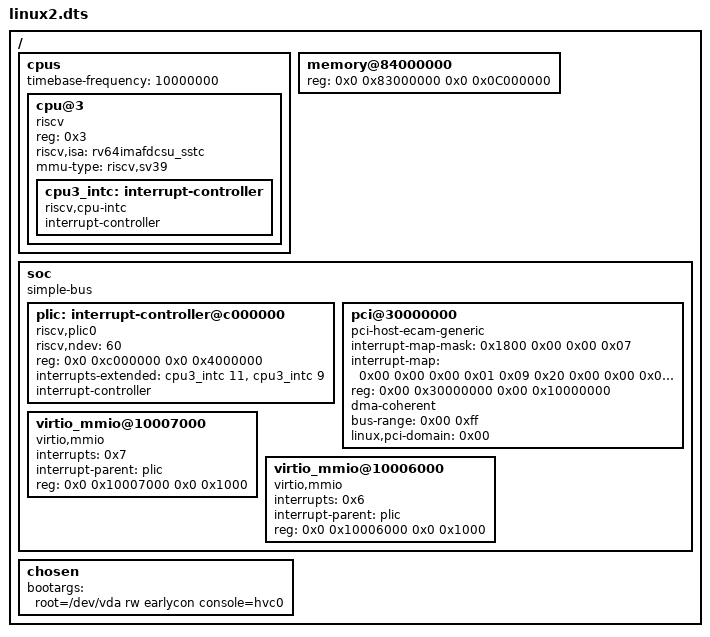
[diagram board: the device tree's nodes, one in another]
/dts-v1/;

/ {
	#address-cells = <0x2>;
	#size-cells = <0x2>;

	cpus {
		#address-cells = <0x1>;
		#size-cells = <0x0>;
		timebase-frequency = <10000000>;
		cpu@3 {
			device_type = "cpu";
			reg = <0x3>;
			status = "okay";
			compatible = "riscv";
			riscv,isa = "rv64imafdcsu_sstc";
			mmu-type = "riscv,sv39";

			cpu3_intc: interrupt-controller {
				#interrupt-cells = <0x1>;
				interrupt-controller;
				compatible = "riscv,cpu-intc";
			};
		};

	};

	memory@84000000 {
		device_type = "memory";
		reg = <0x0 0x83000000 0x0 0x0C000000>;
	};

soc{
		#address-cells = <0x02>;
		#size-cells = <0x02>;
		compatible = "simple-bus";
		ranges;

	plic: interrupt-controller@c000000 {
		riscv,ndev = <60>;
		reg = <0x0 0xc000000 0x0 0x4000000>;
		interrupts-extended = <
			&cpu3_intc 11 &cpu3_intc 9
		>;
		interrupt-controller;
		compatible = "riscv,plic0";
		#interrupt-cells = <0x1>;
		phandle = <0x09>;
	};

	pci@30000000 {
			interrupt-map-mask = <0x1800 0x00 0x00 0x07>;
			interrupt-map = <0x00 0x00 0x00 0x01 0x09 0x20 0x00 0x00 0x00 0x02 0x09 0x21 0x00 0x00 0x00 0x03 0x09 0x22 0x00 0x00 0x00 0x04 0x09 0x23 0x800 0x00 0x00 0x01 0x09 0x21 0x800 0x00 0x00 0x02 0x09 0x22 0x800 0x00 0x00 0x03 0x09 0x23 0x800 0x00 0x00 0x04 0x09 0x20 0x1000 0x00 0x00 0x01 0x09 0x22 0x1000 0x00 0x00 0x02 0x09 0x23 0x1000 0x00 0x00 0x03 0x09 0x20 0x1000 0x00 0x00 0x04 0x09 0x21 0x1800 0x00 0x00 0x01 0x09 0x23 0x1800 0x00 0x00 0x02 0x09 0x20 0x1800 0x00 0x00 0x03 0x09 0x21 0x1800 0x00 0x00 0x04 0x09 0x22>;
			ranges = <0x1000000 0x00 0x00 0x00 0x3000000 0x00 0x10000 0x2000000 0x00 0x40000000 0x00 0x40000000 0x00 0x40000000 0x3000000 0x04 0x00 0x04 0x00 0x04 0x00>;
			reg = <0x00 0x30000000 0x00 0x10000000>;
			dma-coherent;
			bus-range = <0x00 0xff>;
			linux,pci-domain = <0x00>;
			device_type = "pci";
			compatible = "pci-host-ecam-generic";
			#size-cells = <0x02>;
			#interrupt-cells = <0x01>;
			#address-cells = <0x03>;
	};

	// serial
	virtio_mmio@10007000 {
		interrupts = <0x7>;
		interrupt-parent = <&plic>;
		reg = <0x0 0x10007000 0x0 0x1000>;
		compatible = "virtio,mmio";
	};

	// blk
	virtio_mmio@10006000 {
		interrupts = <0x6>;
		interrupt-parent = <&plic>;
		reg = <0x0 0x10006000 0x0 0x1000>;
		compatible = "virtio,mmio";
	};

};
	chosen {
		bootargs = "root=/dev/vda rw earlycon console=hvc0";
	};

};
